# V32F20x_CM33 register map
File version: 1.0.3
CPU: CM33 r0p4, little endian, MPU, FPU, DSP, 3 interrupt priority bits, 8 SAU regions
Registers are 32-bit, read-write, reset 0x0 unless marked. A register's access mark holds for its fields unless they carry their own. Offsets are from the block's base; [hi:lo] are bit positions; {n}, {i} and the like mark numbered series.

## SYSCFG0 — SYSCFG0 Peripheral Interface
Base 0x40200000
Same registers: SEC_SYSCFG0 0x50200000
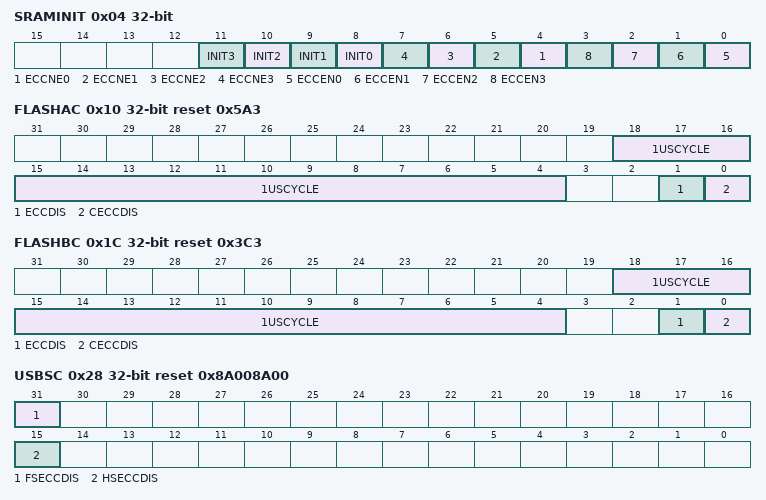
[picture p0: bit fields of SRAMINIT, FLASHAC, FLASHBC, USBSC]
0x04 SRAMINIT — SRAM initialize and ECC configure register.
  [n+8] INIT{n} (n=0..3) — SRAM {n} initial control initial done signal will clear it automatically
  [n+4] ECCNE{n} (n=0..3) — SRAM{n} ECC error NMI enable register.
  [n] ECCEN{n} (n=0..3) — SRAM{n} ECC check 2 bit error detect enable register
0x10 FLASHAC reset 0x5A3 — Flash A control register.
  [18:4] 1USCYCLE — This register is used for flashA controller to calculate 1us tick from AHB clock
  [1] ECCDIS — Flash ECC disable control
  [0] CECCDIS — Flash Cache ECC disable control
0x14 FLASHBANKSWT — Dual bank Flash switch register.
  [0] SWT — Flash dual bank switch
0x1C FLASHBC reset 0x3C3 — Flash B control register.
  [18:4] 1USCYCLE — This register is used for flashB controller to calculate 1us tick from AHB clock
  [1] ECCDIS — Flash ECC disable control
  [0] CECCDIS — Flash Cache ECC disable control
0x28 USBSC reset 0x8A008A00 — USB SRAM control register.
  [31] FSECCDIS — ECC disable control in USBFS SRAM
  [15] HSECCDIS — ECC disable in USBHS SRAM
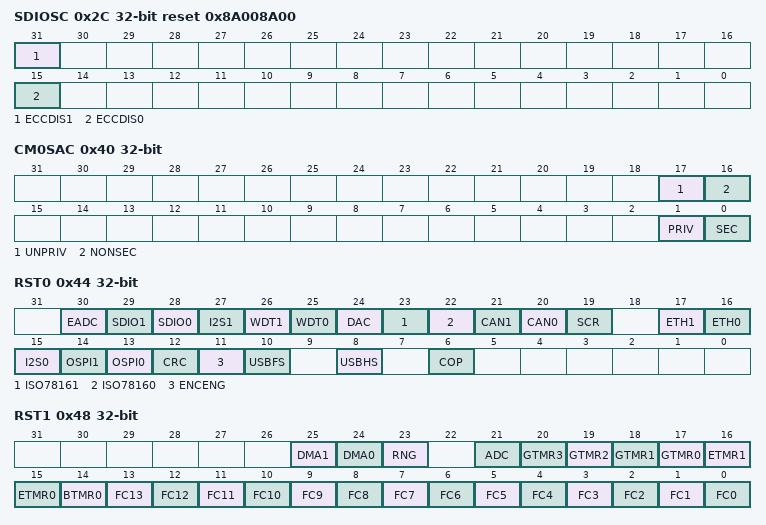
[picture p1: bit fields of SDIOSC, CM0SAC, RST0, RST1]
0x2C SDIOSC reset 0x8A008A00 — SDIO SRAM control register.
  [31] ECCDIS1 — ECC disable control in SDIO1 SRAM
  [15] ECCDIS0 — ECC disable conltrol in SDIO0 SRAM
0x3C CORE1RST reset 0x1 — CM33 CORE1 system reset request register.
  [0] RST — CM33 CORE1 system reset signal control.
0x40 CM0SAC — CM0 security and access permission control register
  [17] UNPRIV — Configure CM0 master transfer to un privilege mode
  [16] NONSEC — Configure CM0 master transfer mode to non secure mode
  [1] PRIV — Configure CM0 master transfer mode to privilege mode
  [0] SEC — Configure CM0 master transfer mode to secure mode.
0x44 RST0 — Peripheral reset control register 0.
  [30] EADC — To reset EADC programmer should set this bit to 1
  [29] SDIO1 — To reset SDIO1 programmer should set this bit to 1
  [28] SDIO0 — To reset SDIO0 programmer should set this bit to 1
  [27] I2S1 — To reset I2S1 programmer should set this bit to 1
  [26] WDT1 — To reset WDT1 programmer should set this bit to 1
  [25] WDT0 — To reset WDT0 programmer should set this bit to 1
  [24] DAC — To reset DAC programmer should set this bit to 1
  [23] ISO78161 — To reset ISO78161 programmer should set this bit to 1
  [22] ISO78160 — To reset ISO78160 programmer should set this bit to 1
  [21] CAN1 — To reset CAN1 programmer should set this bit to 1
  [20] CAN0 — To reset CAN0 programmer should set this bit to 1
  [19] SCR — To reset SCR programmer should set this bit to 1
  [17] ETH1 — To reset ETH1 programmer should set this bit to 1
  [16] ETH0 — To reset ETH0 programmer should set this bit to 1
  [15] I2S0 — To reset I2S0 programmer should set this bit to 1
  [14] OSPI1 — To reset OSPI1 programmer should set this bit to 1
  [13] OSPI0 — To reset OSPI0 programmer should set this bit to 1
  [12] CRC — To reset CRC programmer should set this bit to 1
  [11] ENCENG — To reset ENCENG programmer should set this bit to 1
  [10] USBFS — To reset USBFS programmer should set this bit to 1
  [8] USBHS — To reset USBHS programmer should set this bit to 1
  [6] COP — To reset COP programmer should set this bit to 1
0x48 RST1 — Peripheral reset control register 1.
  [25] DMA1 — To reset DMA1 programmer should set this bit to 1
  [24] DMA0 — To reset DMA0 programmer should set this bit to 1
  [23] RNG — To reset RNG programmer should set this bit to 1
  [21] ADC — To reset ADC programmer should set this bit to 1
  [n+17] GTMR{n} (n=0..3) — To reset GTMR{n} programmer should set this bit to 1
  [16] ETMR1 — To reset ETMR1 programmer should set this bit to 1
  [15] ETMR0 — To reset ETMR0 programmer should set this bit to 1
  [14] BTMR0 — To reset BTMR0 3 programmer should set this bit to 1
  [n] FC{n} (n=0..13) — To reset Flexcomm{n} programmer should set this bit to 1
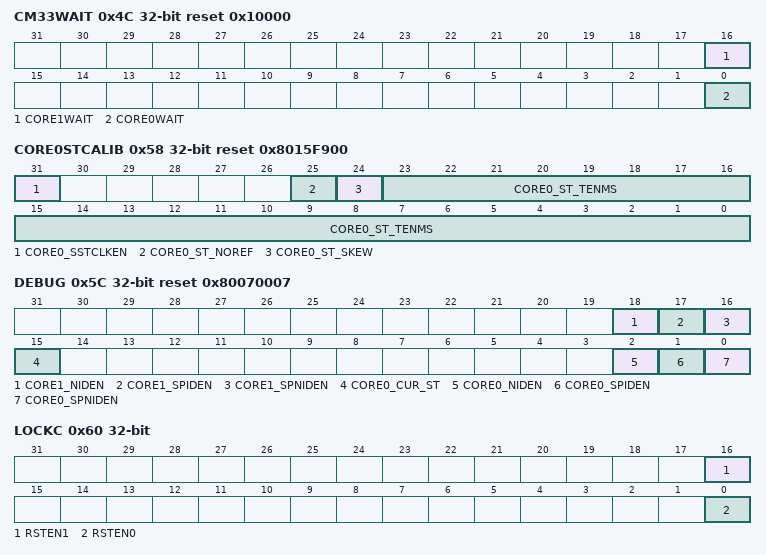
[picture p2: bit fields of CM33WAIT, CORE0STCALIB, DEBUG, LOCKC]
0x4C CM33WAIT reset 0x10000 — CM33 wait signal control register.
  [16] CORE1WAIT, [0] CORE0WAIT
0x50 DSLEEPEN — CM33 deep sleep mode enable register.
  [0] DSLEEPEN — This bit indicates the CM33 CORE0 or CORE1 control CM33 system enter deep sleep mode
0x54 SLEEPEN — CM33 sleep mode enable register.
  [0] SLEEPEN — This bit indicates the CM33 CORE0 or CORE1 control CM33 system enter sleep mode
0x58 CORE0STCALIB reset 0x8015F900 — CM33 CORE0 system tick calibration register.
  [31] CORE0_SSTCLKEN — SysTick clock enable for secure system
  [25] CORE0_ST_NOREF — Indicates that no alternative reference clock source has been integrated
  [24] CORE0_ST_SKEW — 0x0 The system tick clock can guarantee an exact multiple of 10ms
  [23:0] CORE0_ST_TENMS — Integer value to compute a 10ms delay.
0x5C DEBUG reset 0x80070007 — CM33 debug configuration register.
  [18] CORE1_NIDEN — CM33 CORE1 Non-invasive debug enabled.
  [17] CORE1_SPIDEN — CM33 CORE1 Secure invasive debug enabled.
  [16] CORE1_SPNIDEN — CM33 CORE1 Secure non-invasive debug enabled
  [15] CORE0_CUR_ST — Current CORE0 Secure State.
  [2] CORE0_NIDEN — CM33 CORE0 Non-invasive debug enabled.
  [1] CORE0_SPIDEN — CM33 CORE0 Secure invasive debug enabled.
  [0] CORE0_SPNIDEN — CM33 CORE0 Secure non-invasive debug enabled
0x60 LOCKC — CM33 lockup control register.
  [16] RSTEN1 — CM33 CORE1 reset enable when lockup occurred.
  [0] RSTEN0 — CM33 CORE0 reset enable when lockup occurred.
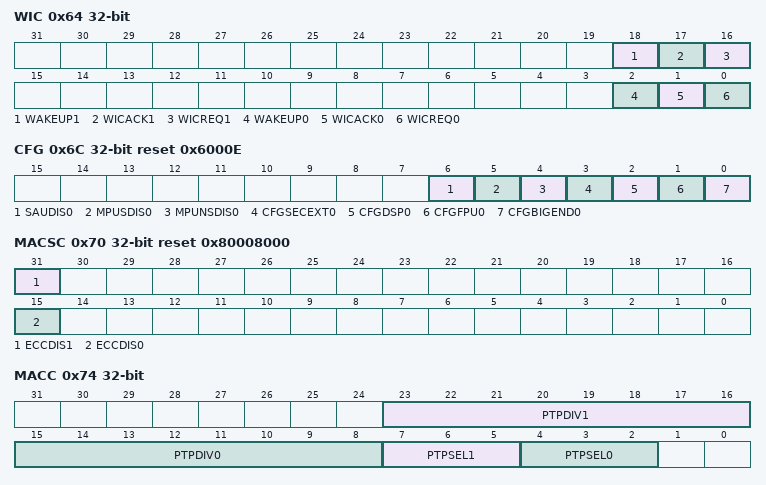
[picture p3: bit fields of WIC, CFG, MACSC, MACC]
0x64 WIC — CM33 WIC control register.
  [18] WAKEUP1 — WIC WAKEUP signal from CM33 CORE1
  [17] WICACK1 — WIC ACK from CM33 CORE1
  [16] WICREQ1 — CM33 CORE1 WIC request
  [2] WAKEUP0 — WIC WAKEUP signal from CM33 CORE0
  [1] WICACK0 — WIC ACK from CM33 CORE0
  [0] WICREQ0 — CM33 CORE0 WIC request
0x6C CFG reset 0x6000E — CM33 configure register.
  [6] SAUDIS0 — CM33 CORE0 SAU disable control
  [5] MPUSDIS0 — CM33 CORE0 secure MPU disable control
  [4] MPUNSDIS0 — CM33 CORE0 non-secure MPU disable control
  [3] CFGSECEXT0 — CM33 CORE0 Armv8
  [2] CFGDSP0 — CM33 CORE0 Armv8.M DSP extension enable control
  [1] CFGFPU0 — CM33 CORE0 hardware floating-point enable control
  [0] CFGBIGEND0 — CM33 CORE0 static endianness selection for data accesses
0x70 MACSC reset 0x80008000 — MAC SRAM control register.
  [31] ECCDIS1 — ECC disable control in ETH1
  [15] ECCDIS0 — ECC disable control in ETH0 SRAM:
0x74 MACC — MAC control register.
  [23:16] PTPDIV1 — ETH1 PTP reference clock divider
  [15:8] PTPDIV0 — ETH0 PTP reference clock divider
  [7:5] PTPSEL1 — ETH1 PTP reference clock source selection
  [4:2] PTPSEL0 — ETH0 PTP reference clock source selection
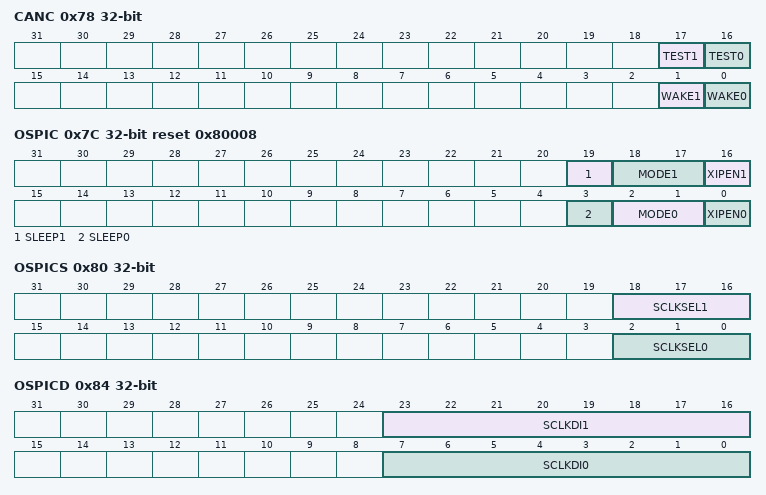
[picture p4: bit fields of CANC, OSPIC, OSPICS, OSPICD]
0x78 CANC — CAN control Register.
  [17] TEST1 — CAN1 TEST signal
  [16] TEST0 — CAN0 TEST signal
  [1] WAKE1 — CAN1 wake signal
  [0] WAKE0 — CAN0 wake signal
0x7C OSPIC reset 0x80008 — OSPI control and status register.
  [19] SLEEP1 — OSPI1 enable flag
  [18:17] MODE1 — OSPI1 mode status
  [16] XIPEN1 — OSPI1 XIP mode enable control:
  [3] SLEEP0 — OSPI0 enable flag
  [2:1] MODE0 — OSPI0 mode status
  [0] XIPEN0 — OSPI0 XIP mode enable control
0x80 OSPICS — OSPI clock source select register.
  [18:16] SCLKSEL1 — OSPI1 clock source selection
  [2:0] SCLKSEL0 — OSPI1 clock source selection
0x84 OSPICD — OSPI clock divider register.
  [23:16] SCLKDI1 — This register is used to control OSPI1 clock divider
  [7:0] SCLKDI0 — This register is used to control OSPI0 clock divider
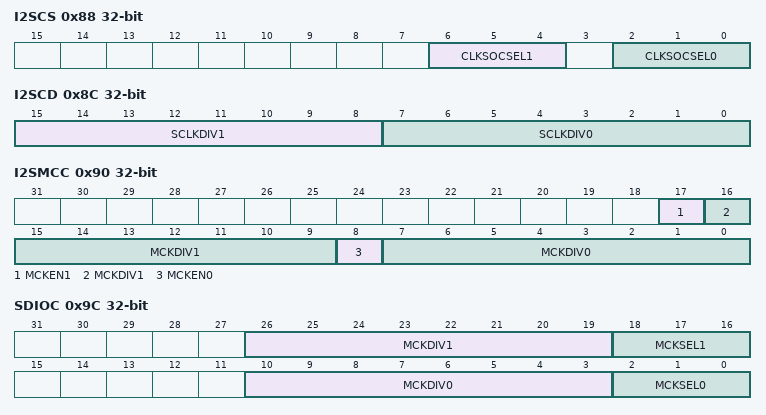
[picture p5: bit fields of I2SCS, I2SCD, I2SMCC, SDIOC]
0x88 I2SCS — I2S clock source select register.
  [6:4] CLKSOCSEL1 — This register is used to select I2S1 clock from SOC source
  [2:0] CLKSOCSEL0 — This register is used to select I2S0 clock from SOC source
0x8C I2SCD — I2S clock divider register.
  [15:8] SCLKDIV1 — This register is used to control I2S1 clock divider
  [7:0] SCLKDIV0 — This register is used to control I2S0 clock divider
0x90 I2SMCC — I2S master clock control register.
  [17] MCKEN1 — I2S1 master clock output enable
  [16:9] MCKDIV1 — This register is used to control I2S1 master clock divider
  [8] MCKEN0 — I2S0 master clock output enable:
  [7:0] MCKDIV0 — This register is used to control I2S0 master clock divider
0x9C SDIOC — SDIO control register.
  [26:19] MCKDIV1 — This register is used to control SDIO1 clock divider
  [18:16] MCKSEL1 — This register is used to control SDIO1 clock source
  [10:3] MCKDIV0 — This register is used to control SDIO0 clock divider
  [2:0] MCKSEL0 — This register is used to control SDIO0 clock source
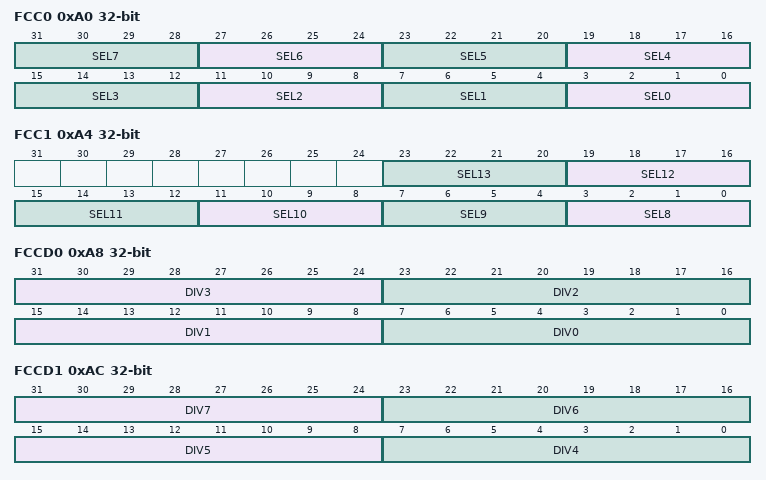
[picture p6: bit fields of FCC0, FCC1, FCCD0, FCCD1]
0xA0 FCC0 — Flexcomm control register 0.
  [4n+3:4n] SEL{n} (n=0..7) — Flexcomm {n} peripheral selection, only one hot
0xA4 FCC1 — Flexcomm control register 1.
  [4n-29:4n-32] SEL{n} (n=8..13) — Flexcomm {n} peripheral selection, only one hot
0xA8 FCCD0 — Flexcomm clock divider control register 0.
  [31:24] DIV3 — Flexcomm 3 clock divider
  [23:16] DIV2 — Flexcomm 2 clock divider
  [15:8] DIV1 — Flexcomm 1 clock divider
  [7:0] DIV0 — Flexcomm 0 clock divider:
0xAC FCCD1 — Flexcomm clock divider control register 1.
  [31:24] DIV7 — Flexcomm 7 clock divider
  [23:16] DIV6 — Flexcomm 6 clock divider
  [15:8] DIV5 — Flexcomm 5 clock divider:
  [7:0] DIV4 — Flexcomm 0 clock divider:
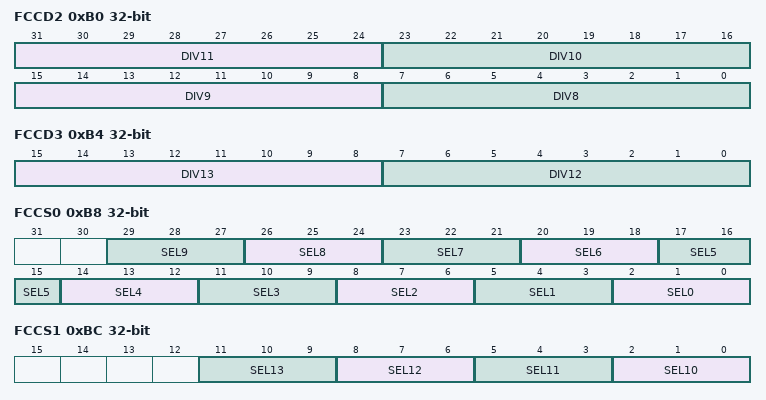
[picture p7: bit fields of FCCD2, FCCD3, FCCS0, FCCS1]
0xB0 FCCD2 — Flexcomm clock divider control register 2.
  [31:24] DIV11 — Flexcomm 11 clock divider
  [23:16] DIV10 — Flexcomm 10 clock divider
  [15:8] DIV9 — Flexcomm 9 clock divider
  [7:0] DIV8 — Flexcomm8 clock divider
0xB4 FCCD3 — Flexcomm clock divider control register 3.
  [15:8] DIV13 — Flexcomm 13 clock divider
  [7:0] DIV12 — Flexcomm 12 clock divider:
0xB8 FCCS0 — Flexcomm clock select register 0.
  [3n+2:3n] SEL{n} (n=0..9) — This register is used to select Flexcomm {n} clock source
0xBC FCCS1 — Flexcomm clock select register 1.
  [3n-28:3n-30] SEL{n} (n=10..13) — This register is used to select Flexcomm {n} clock source
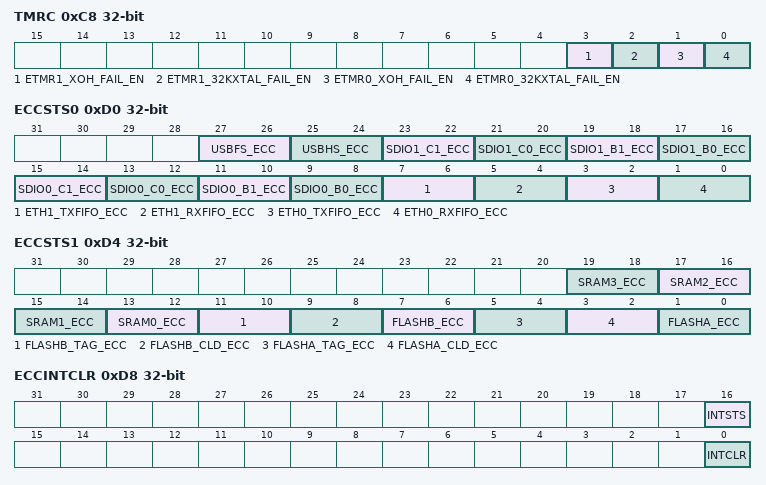
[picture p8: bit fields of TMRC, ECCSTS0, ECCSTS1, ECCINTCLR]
0xC8 TMRC — Timer configure register.
  [3] ETMR1_XOH_FAIL_EN — ETMR1 XOH clock fail enable signal.
  [2] ETMR1_32KXTAL_FAIL_EN — ETMR1 32K XTAL clock fail enable signal.
  [1] ETMR0_XOH_FAIL_EN — ETMR0 XOH clock fail enable signal.
  [0] ETMR0_32KXTAL_FAIL_EN — ETMR0 XOL clock fail enable signal.
0xD0 ECCSTS0 ro — Memory ECC status register 0.
  [27:26] USBFS_ECC — USB_FS ECC status
  [25:24] USBHS_ECC — USB_HS ECC status
  [23:22] SDIO1_C1_ECC — SDIO1 C1 ECC status
  [21:20] SDIO1_C0_ECC — SDIO1 C0 ECC status
  [19:18] SDIO1_B1_ECC — SDIO1 B1 ECC status
  [17:16] SDIO1_B0_ECC — SDIO1 B0 ECC status
  [15:14] SDIO0_C1_ECC — SDIO0 C1 ECC status
  [13:12] SDIO0_C0_ECC — SDIO0 C0 ECC status
  [11:10] SDIO0_B1_ECC — SDIO0 B1 ECC status
  [9:8] SDIO0_B0_ECC — SDIO0 B0 ECC status
  [7:6] ETH1_TXFIFO_ECC — ETH1 TX FIFO ECC status
  [5:4] ETH1_RXFIFO_ECC — ETH1 RX FIFO ECC status
  [3:2] ETH0_TXFIFO_ECC — ETH0 TX FIFO ECC status
  [1:0] ETH0_RXFIFO_ECC — ETH0 RX FIFO ECC status
0xD4 ECCSTS1 ro — Memory ECC status register 1.
  [2n+13:2n+12] SRAM{n}_ECC (n=0..3) — SRAM{n} ECC status
  [11:10] FLASHB_TAG_ECC — Flash B tag ECC status
  [9:8] FLASHB_CLD_ECC — Flash B cld ECC status
  [7:6] FLASHB_ECC — Flash B ECC status
  [5:4] FLASHA_TAG_ECC — Flash A tag ECC status
  [3:2] FLASHA_CLD_ECC — Flash A cld ECC status
  [1:0] FLASHA_ECC — Flash A ECC status
0xD8 ECCINTCLR — Memory ECC interrupt clear register.
  [16] INTSTS — Memory ECC interrupt status.
  [0] INTCLR — Memory ECC interrupt clear.
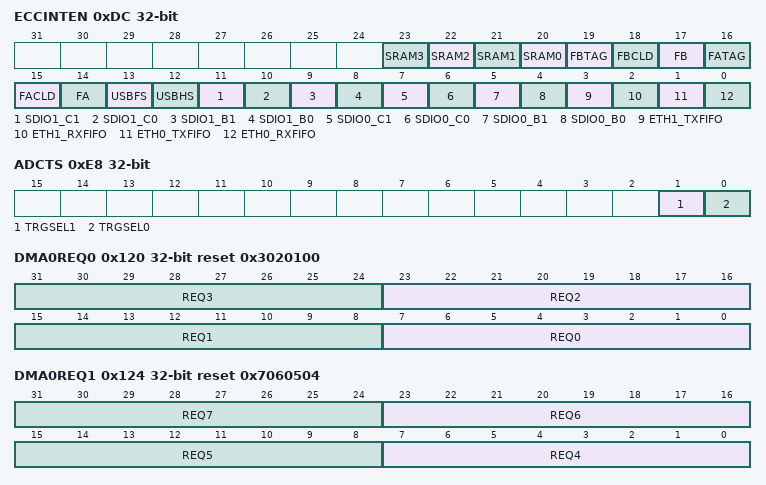
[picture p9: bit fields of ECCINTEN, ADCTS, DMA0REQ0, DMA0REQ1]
0xDC ECCINTEN — Memory ECC interrupt enable register.
  [n+20] SRAM{n} (n=0..3) — SRAM{n} ECC interrupt enable
  [19] FBTAG — Flash B tag ECC interrupt enable
  [18] FBCLD — Flash B cld ECC interrupt enable
  [17] FB — Flash B ECC interrupt enable
  [16] FATAG — Flash A tag ECC interrupt enable
  [15] FACLD — Flash A cld ECC interrupt enable
  [14] FA — Flash A ECC interrupt enable
  [13] USBFS — USBFS ECC interrupt enable
  [12] USBHS — USBHS ECC interrupt enable
  [11] SDIO1_C1 — SDIO0 C1 ECC interrupt enable
  [10] SDIO1_C0 — SDIO0 C0 ECC interrupt enable
  [9] SDIO1_B1 — SDIO1 B1 ECC interrupt enable
  [8] SDIO1_B0 — SDIO1 B0 ECC interrupt enable
  [7] SDIO0_C1 — SDIO0 C1 ECC interrupt enable
  [6] SDIO0_C0 — SDIO0 C0 ECC interrupt enable
  [5] SDIO0_B1 — SDIO0 B1 ECC interrupt enable
  [4] SDIO0_B0 — SDIO0 B0 ECC interrupt enable
  [3] ETH1_TXFIFO — ETH1 TXFIFO ECC interrupt enable
  [2] ETH1_RXFIFO — ETH1 RXFIFO ECC interrupt enable
  [1] ETH0_TXFIFO — ETH0 TXFIFO ECC interrupt enable
  [0] ETH0_RXFIFO — ETH0 RXFIFO ECC interrupt enable
0xE0 ADCCS — ADC clock source select register.
  [2:0] SEL — ADC clock source select
0xE4 ADCCD — ADC clock divider configure register.
  [7:0] DIV — ADC clock divider
0xE8 ADCTS — ADC trigger source select register.
  [1] TRGSEL1 — Select ADC trigger source
  [0] TRGSEL0 — Select ADC trigger source
0x118 CORE1CSADDR — CM33 CORE1 code snooper restart address register.
  [31:0] ADDR — CM33 CORE1 code snooper restart address after reset
0x120 DMA0REQ0 reset 0x3020100 — DMA0 request select register 0.
  [8n+7:8n] REQ{n} (n=0..3) — DMA0 request source select.
0x124 DMA0REQ1 reset 0x7060504 — DMA0 request select register 1.
  [8n-25:8n-32] REQ{n} (n=4..7) — DMA0 request source select.
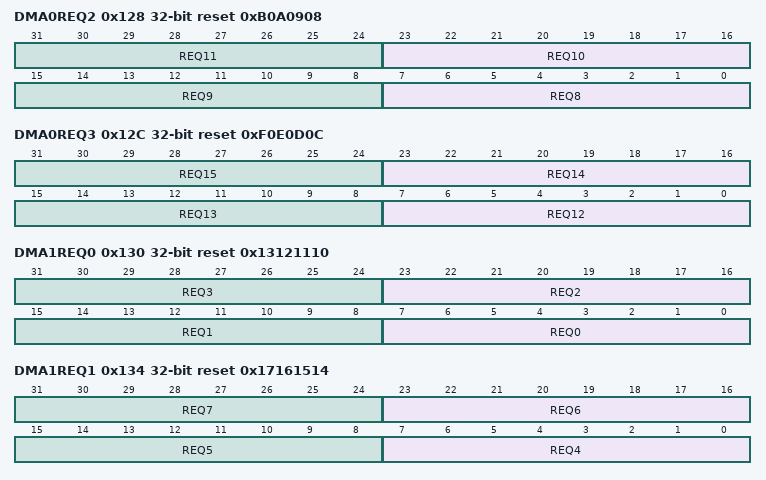
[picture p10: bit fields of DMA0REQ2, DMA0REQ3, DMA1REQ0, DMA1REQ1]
0x128 DMA0REQ2 reset 0xB0A0908 — DMA0 request select register 2.
  [8n-57:8n-64] REQ{n} (n=8..11) — DMA0 request source select.
0x12C DMA0REQ3 reset 0xF0E0D0C — DMA0 request select register 3.
  [8n-89:8n-96] REQ{n} (n=12..15) — DMA0 request source select.
0x130 DMA1REQ0 reset 0x13121110 — DMA1 request select register 0.
  [8n+7:8n] REQ{n} (n=0..3) — DMA1 request source select.
0x134 DMA1REQ1 reset 0x17161514 — DMA1 request select register 1.
  [8n-25:8n-32] REQ{n} (n=4..7) — DMA1 request source select.
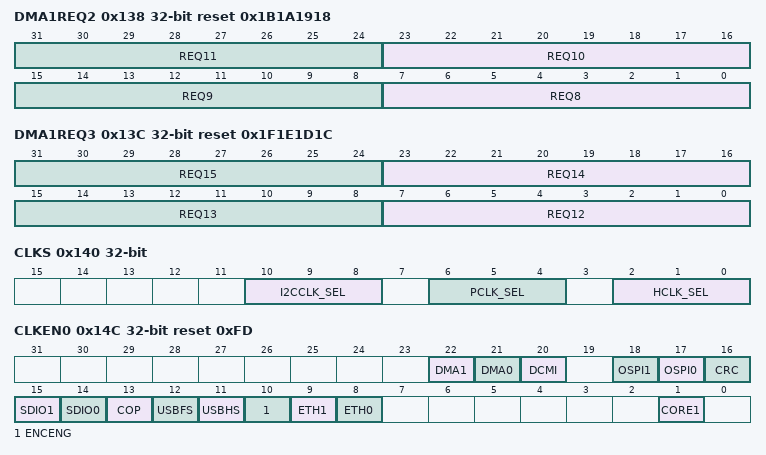
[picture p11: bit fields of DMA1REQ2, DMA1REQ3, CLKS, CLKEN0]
0x138 DMA1REQ2 reset 0x1B1A1918 — DMA1 request select register 2.
  [8n-57:8n-64] REQ{n} (n=8..11) — DMA1 request source select.
0x13C DMA1REQ3 reset 0x1F1E1D1C — DMA1 request select register 3.
  [8n-89:8n-96] REQ{n} (n=12..15) — DMA1 request source select.
0x140 CLKS — Clock selection register.
  [10:8] I2CCLK_SEL — This register is used to select I2C clock source
  [6:4] PCLK_SEL — This register is used to select APB0 clock source
  [2:0] HCLK_SEL — This register is used to select AHB0 clock source.
0x144 HCLKD — AHB Bus clock divider control register.
  [7:0] DIV — This register is used to control AHB0 clock divider
0x148 PCLKD — APB clock divider control register.
  [7:0] DIV — This register is used to control APB0 clock divider
0x14C CLKEN0 reset 0xFD — Peripheral clock enable control register 0.
  [22] DMA1 — DMA1 HCLK enable
  [21] DMA0 — DMA0 HCLK enable
  [20] DCMI — DCMI PCLK enable PCLK frequency is the same as HCLK
  [18] OSPI1 — OSPI1 HCLK SCLK enable PCLK frequency is the same as HCLK
  [17] OSPI0 — OSPI0 HCLK SCLK enable PCLK frequency is the same as HCLK
  [16] CRC — CRC HCLK enable PCLK frequency is the same as HCLK
  [15] SDIO1 — SDIO1 HCLK enable PCLK frequency is the same as HCLK
  [14] SDIO0 — SDIO0 HCLK enable PCLK frequency is the same as HCLK
  [13] COP — COP HCLK enable PCLK frequency is the same as HCLK
  [12] USBFS — USB_FS HCLK enable PCLK frequency is the same as HCLK
  [11] USBHS — USB_HS HCLK enable PCLK frequency is the same as HCLK
  [10] ENCENG — ENCENG HCLK enable PCLK frequency is the same as HCLK
  [9] ETH1 — ETH1 PCLK enable PCLK frequency is the same as HCLK
  [8] ETH0 — ETH0 PCLK enable PCLK frequency is the same as HCLK
  [1] CORE1 — CM33 CORE1 HCLK enable
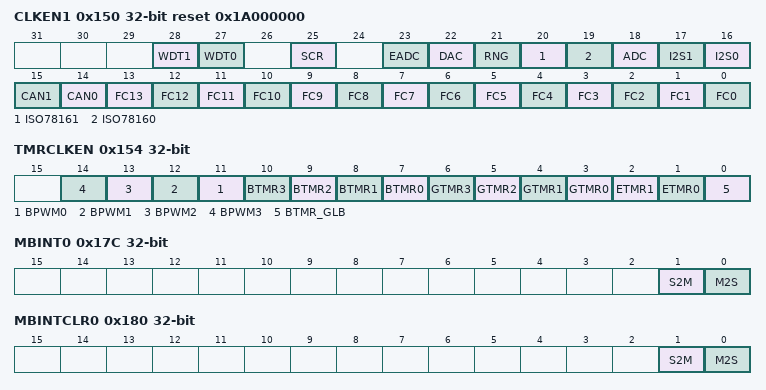
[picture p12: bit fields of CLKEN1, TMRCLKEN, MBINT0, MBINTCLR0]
0x150 CLKEN1 reset 0x1A000000 — Peripheral clock enable control register 1.
  [28] WDT1 — WDT1 PCLK enable
  [27] WDT0 — WDT0 PCLK enable
  [25] SCR — SCR PCLK enable
  [23] EADC — EADC PCLK/CLK enable
  [22] DAC — DAC PCLK/CLK enable
  [21] RNG — RNG PCLK enable
  [20] ISO78161 — ISO78161 PCLK enable
  [19] ISO78160 — ISO78160 PCLK enable
  [18] ADC — ADC PCLK/SCLK enable
  [17] I2S1 — I2S1 PCLK/SCLK enable
  [16] I2S0 — I2S0 PCLK/SCLK enable
  [15] CAN1 — CAN1 SCLK/PCLK enable
  [14] CAN0 — CAN0 SCLK/PCLK enable
  [n] FC{n} (n=0..13) — FLEXCOMM{n} SCLK/PCLK enable
0x154 TMRCLKEN — Timer APB clock enable control register.
  [n+11] BPWM{n} (n=0..3) — Basic PWM timer {n} (BPWM{n}) clock enable
  [n+7] BTMR{n} (n=0..3) — Basic timer {n} (BTMR{n}) clock enable
  [n+3] GTMR{n} (n=0..3) — GTMR{n} PCLK enable
  [2] ETMR1 — ETMR1 PCLK enable
  [1] ETMR0 — ETMR0 PCLK enable
  [0] BTMR_GLB — BTMR0~3 and BPWM0~3 global PCLK enable
0x158 DACCS — DAC clock source select register.
  [2:0] SEL — This register is used to select DAC clock from SOC source
0x15C DACCD — DAC clock divider register.
  [7:0] DIV — This register is used to control DAC clock divider
0x160 EADCCS — EADC clock source select register.
  [2:0] SEL — This register is used to control EDAC clock form SOC source
0x164 EADCCD — EADC clock divider register.
  [7:0] DIV — This register is used to control EADC clock divider
0x168 USBHSCS — USBHS clock source select register.
  [2:0] SEL — This register is used to control USB_HS clock source
0x16C USBHSCD — USBHS clock divider register.
  [7:0] DIV — This register is used to control USB_HS clock divider
0x170 USBFSCS — USBFS clock source select register.
  [2:0] SEL — This register is used to control USB_FS clock source
0x174 USBFSCD — USBFS clock divider register.
  [7:0] DIV — This register is used to control USB_FS clock divider
0x178 MBMUTEX reset 0x1 — Mailbox CM33 CORE0 and CM33 CORE1 mutually exclusive register
  [0] EX — CM33 CORE0 and CORE1 mailbox mutual exclusion register
0x17C MBINT0 wo — Mailbox CM33 CORE0 and CM33 CORE1 interrupt set register
  [1] S2M — When CM33 CORE1 will connect with CM33 CORE0 CORE1 will write 1 to this bit and interrupt will generate to CORE0
  [0] M2S — When CM33 CORE0 will connect with CM33 CORE1 CORE0 will write 1 to this bit and interrupt will generate to CORE1
0x180 MBINTCLR0 wo — Mailbox CM33 CORE0 and CM33 CORE1 interrupt clear register
  [1] S2M — When write 1 to this bit the interrupt CORE1 generate to CORE0 will be cleared
  [0] M2S — When write 1 to this bit the interrupt CORE0 generate to CORE1 will be cleared
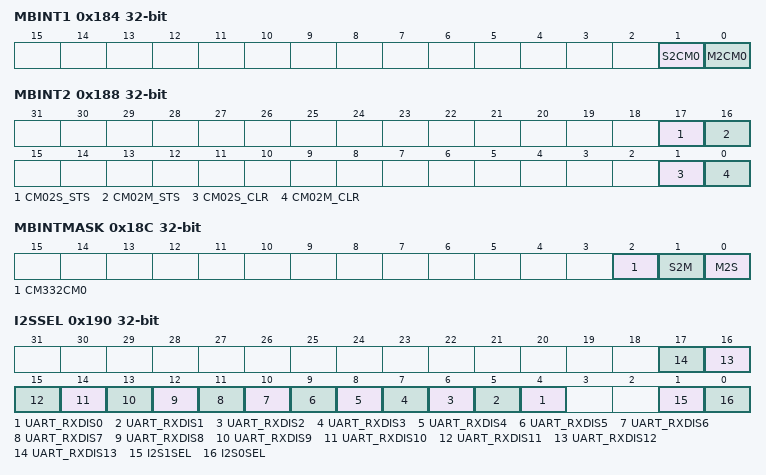
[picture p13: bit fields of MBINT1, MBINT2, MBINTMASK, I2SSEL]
0x184 MBINT1 wo — Mailbox CM33 CORE0 and CM0 interrupt set register.
  [1] S2CM0 — When CM33 CORE1 will connect with CM0 CORE1 will write 1 to this bit and interrupt will generate to CM0
  [0] M2CM0 — When CM33 CORE0 will connect with CM0 CORE0 will write 1 to this bit and interrupt will generate to CM0
0x188 MBINT2 — Mailbox CM0 to CM33 interrupt clear and interrupt status register
  [17] CM02S_STS — CM0 to CM33 CORE1 interrupt status high is active
  [16] CM02M_STS — CM0 to CM33 CORE0 interrupt status high is active
  [1] CM02S_CLR — When write 1 to this bit the interrupt CM0 to CM33 CORE1 be cleared
  [0] CM02M_CLR — When write 1 to this bit the interrupt CM0 to CM33 CORE0 be cleared
0x18C MBINTMASK — Mailbox interrupt mask register.
  [2] CM332CM0 — CM33 CORE0 and CORE1 to CM0 interrupt mask signal
  [1] S2M — CM33 CORE1 to CORE0 interrupt mask signal
  [0] M2S — CM33 CORE0 to CORE1 interrupt mask signal
0x190 I2SSEL — Flexcomm and I2S function selection register.
  [n+4] UART_RXDIS{n} (n=0..13) — Flexcomm{n} UART RX function disable
  [1] I2S1SEL — Flexcomm5 and I2S1 share the same pins so need select one function
  [0] I2S0SEL — Flexcomm4 and I2S0 share the same pins so need select one function
0x194 SYSCFGLPC — SYSCFGLP control register.
  [1] RST — SYSCFGLP bridge reset signal.
0x198 DBGCFG — Debug mode configure register.
  [0] DBGEN — Debug enable signal
0x1A0 PASSWD wo — Write access protection password register.
  [31:0] PASSWD — Write 0xBEEF_BEEF to this register to unlock the write access to some password protect register
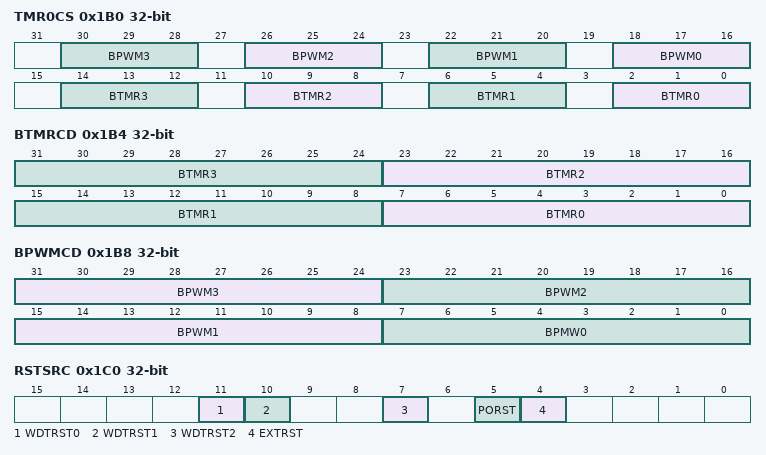
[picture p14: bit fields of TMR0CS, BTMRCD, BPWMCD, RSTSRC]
0x1B0 TMR0CS — Timer0 clock select register.
  [4n+18:4n+16] BPWM{n} (n=0..3) — This register is used to select basic PWM timer {n} BPWM{n} clock source
  [4n+2:4n] BTMR{n} (n=0..3) — This register is used to select basic timer {n} BTMR{n} clock source
0x1B4 BTMRCD — Basic Timer divider configure register.
  [8n+7:8n] BTMR{n} (n=0..3) — This register is used to control basic timer {n} BTMR{n} clock divider
0x1B8 BPWMCD — Basic PWM timer divider configure register.
  [31:24] BPWM3 — This register is used to control basic PWM timer 3 BPWM3 clock divider
  [23:16] BPWM2 — This register is used to control basic PWM timer 2 BPWM2 clock divider
  [15:8] BPWM1 — This register is used to control basic PWM timer 1 BPWM1 clock divider
  [7:0] BPMW0 — This register is used to control basic PWM timer 0 BPWM0 clock divider
0x1C0 RSTSRC ro — Reset source register.
  [11] WDTRST0 — Last reset is cause by WDT0 reset.
  [10] WDTRST1 — Last reset is cause by WDT1 reset.
  [7] WDTRST2 — Last reset is cause by WDT2 reset.
  [5] PORST — Last reset is cause by power-on reset.
  [4] EXTRST — Last reset is cause by external reset.
